# csr register map
Vendor: litex
Litex SoC 2024-01-17 20:17:24
Registers are 32-bit, read-write, reset 0x0 unless marked. A register's access mark holds for its fields unless they carry their own. Offsets are from the block's base; lines under a group give offsets from that group; [hi:lo] are bit positions; {n}, {i} and the like mark numbered series; 'fields as' and 'values as' point back to an identical list; <NAME> marks a mode.

## Memory map
0x82000000 LEDS size 0x4
0x82000800 PANTALLA size 0x1C
0x82001000 CTRL size 0xC
0x82001800 ETHMAC size 0x44
0x82002000 ETHPHY size 0x10
0x82002800 IDENTIFIER_MEM size 0x4
0x82003000 SDRAM size 0x1C
0x82003800 TIMER0 size 0x20
0x82004000 UART size 0x20

## Interrupts
0 uart (UART)
1 timer0 (TIMER0)
2 ethmac (ETHMAC)

## Further device data
memoryRegions:
  ROM baseAddress=0x00000000 size=0x00009800
  SRAM baseAddress=0x01000000 size=0x00002000
  MAIN_RAM baseAddress=0x40000000 size=0x00800000
  ETHMAC baseAddress=0x80000000 size=0x00002000
  CSR baseAddress=0x82000000 size=0x00010000
constants:
  CONFIG_CLOCK_FREQUENCY value=60000000
  CONFIG_CPU_HAS_INTERRUPT value=None
  CONFIG_CPU_RESET_ADDR value=0
  CONFIG_CPU_TYPE_LM32 value=None
  CONFIG_CPU_VARIANT_STANDARD value=None
  CONFIG_CPU_HUMAN_NAME value=LM32
  CONFIG_CPU_NOP value=nop
  CONFIG_L2_SIZE value=8192
  CONFIG_CSR_DATA_WIDTH value=32
  CONFIG_CSR_ALIGNMENT value=32
  CONFIG_BUS_STANDARD value=WISHBONE
  CONFIG_BUS_DATA_WIDTH value=32
  CONFIG_BUS_ADDRESS_WIDTH value=32
  CONFIG_BUS_BURSTING value=0
  ETHMAC_RX_SLOTS value=2
  ETHMAC_TX_SLOTS value=2
  ETHMAC_SLOT_SIZE value=2048
  CONFIG_CPU_INTERRUPTS value=3
  ETHMAC_INTERRUPT value=2
  TIMER0_INTERRUPT value=1
  UART_INTERRUPT value=0

## LEDS
Base 0x82000000
0x00 OUT — GPIO Output(s) Control.
  [0] out

## PANTALLA
Base 0x82000800
0x00 ENABLE
  [0] enable
0x04 WR
  [0] wr
0x08 DATALINE1 — Bits 32-53 of `PANTALLA_DATALINE`.
  [31:0] dataline
0x0C DATALINE0 — Bits 0-31 of `PANTALLA_DATALINE`.
  [31:0] dataline
0x10 ADDRWRITE
  [11:0] addrwrite
0x14 RAMTIME
  [29:0] ramtime
0x18 REQUIREDATA
  [0] requiredata

## CTRL
Base 0x82001000
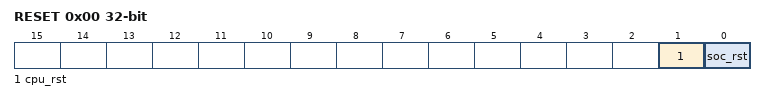
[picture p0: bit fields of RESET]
0x00 RESET
  [1] cpu_rst — Write `1` to this register to reset the CPU(s) of the SoC (Hold Reset)
  [0] soc_rst — Write `1` to this register to reset the full SoC (Pulse Reset)
0x04 SCRATCH reset 0x12345678 — Use this register as a scratch space to verify that software read/write accesses to the Wishbone/CSR bus are working correctly. The initial reset value of 0x1234578 can be used to verify endianness.
0x08 BUS_ERRORS — Total number of Wishbone bus errors (timeouts) since start.

## ETHMAC
Base 0x82001800
0x00 SRAM_WRITER_SLOT
  [0] sram_writer_slot
0x04 SRAM_WRITER_LENGTH
  [10:0] sram_writer_length
0x08 SRAM_WRITER_ERRORS
0x0C SRAM_WRITER_EV_STATUS — This register contains the current raw level of the available event trigger. Writes to this register have no effect.
  [0] available — Level of the ``available`` event
0x10 SRAM_WRITER_EV_PENDING — When a available event occurs, the corresponding bit will be set in this register. To clear the Event, set the corresponding bit in this register.
  [0] available — `1` if a `available` event occurred. This Event is **level triggered** when the signal is **high**.
0x14 SRAM_WRITER_EV_ENABLE — This register enables the corresponding available events. Write a ``0`` to this register to disable individual events.
  [0] available — Write a ``1`` to enable the ``available`` Event
0x18 SRAM_READER_START
  [0] sram_reader_start
0x1C SRAM_READER_READY
  [0] sram_reader_ready
0x20 SRAM_READER_LEVEL
  [1:0] sram_reader_level
0x24 SRAM_READER_SLOT
  [0] sram_reader_slot
0x28 SRAM_READER_LENGTH
  [10:0] sram_reader_length
0x2C SRAM_READER_EV_STATUS — This register contains the current raw level of the event0 event trigger. Writes to this register have no effect.
  [0] event0 — Level of the ``event0`` event
0x30 SRAM_READER_EV_PENDING — When a event0 event occurs, the corresponding bit will be set in this register. To clear the Event, set the corresponding bit in this register.
  [0] event0 — `1` if a this particular event occurred. This Event is triggered on a **rising** edge.
0x34 SRAM_READER_EV_ENABLE — This register enables the corresponding event0 events. Write a ``0`` to this register to disable individual events.
  [0] event0 — Write a ``1`` to enable the ``event0`` Event
0x38 PREAMBLE_CRC reset 0x1
  [0] preamble_crc
0x3C RX_DATAPATH_PREAMBLE_ERRORS
0x40 RX_DATAPATH_CRC_ERRORS

## ETHPHY
Base 0x82002000
0x00 CRG_RESET
  [0] crg_reset
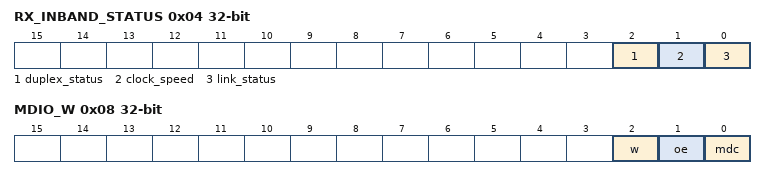
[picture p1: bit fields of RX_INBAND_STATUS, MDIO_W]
0x04 RX_INBAND_STATUS
  [2] duplex_status, [1] clock_speed, [0] link_status
0x08 MDIO_W
  [2] w, [1] oe, [0] mdc
0x0C MDIO_R
  [0] r

## IDENTIFIER_MEM
Base 0x82002800
0x00 IDENTIFIER_MEM — 8 x 45-bit memory
  [7:0] identifier_mem

## SDRAM
Base 0x82003000
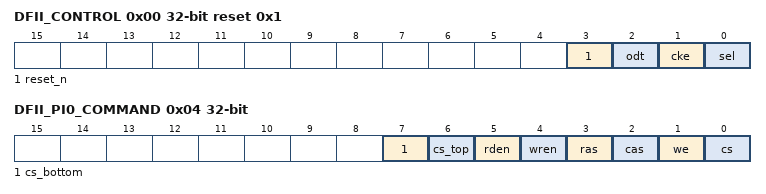
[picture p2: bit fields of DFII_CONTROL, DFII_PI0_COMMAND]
0x00 DFII_CONTROL reset 0x1 — Control DFI signals common to all phases
  [3] reset_n — DFI clock reset bus
  [2] odt — DFI on-die termination bus
  [1] cke — DFI clock enable bus
  [0] sel
0x04 DFII_PI0_COMMAND — Control DFI signals on a single phase
  [7] cs_bottom — DFI chip select bus for bottom half only
  [6] cs_top — DFI chip select bus for top half only
  [5] rden — DFI read data enable bus
  [4] wren — DFI write data enable bus
  [3] ras — DFI row address strobe bus
  [2] cas — DFI column address strobe bus
  [1] we — DFI write enable bus
  [0] cs — DFI chip select bus
0x08 DFII_PI0_COMMAND_ISSUE
  [0] dfii_pi0_command_issue
0x0C DFII_PI0_ADDRESS — DFI address bus
  [10:0] dfii_pi0_address
0x10 DFII_PI0_BADDRESS — DFI bank address bus
  [1:0] dfii_pi0_baddress
0x14 DFII_PI0_WRDATA — DFI write data bus
0x18 DFII_PI0_RDDATA — DFI read data bus

## TIMER0
Base 0x82003800
0x00 LOAD — Load value when Timer is (re-)enabled. In One-Shot mode, the value written to this register specifies the Timer's duration in clock cycles.
0x04 RELOAD — Reload value when Timer reaches ``0``. In Periodic mode, the value written to this register specify the Timer's period in clock cycles.
0x08 EN — Enable flag of the Timer. Set this flag to ``1`` to enable/start the Timer. Set to ``0`` to disable the Timer.
  [0] en
0x0C UPDATE_VALUE — Update trigger for the current countdown value. A write to this register latches the current countdown value to ``value`` register.
  [0] update_value
0x10 VALUE — Latched countdown value. This value is updated by writing to ``update_value``.
0x14 EV_STATUS — This register contains the current raw level of the zero event trigger. Writes to this register have no effect.
  [0] zero — Level of the ``zero`` event
0x18 EV_PENDING — When a zero event occurs, the corresponding bit will be set in this register. To clear the Event, set the corresponding bit in this register.
  [0] zero — `1` if a `zero` event occurred. This Event is triggered on a **falling** edge.
0x1C EV_ENABLE — This register enables the corresponding zero events. Write a ``0`` to this register to disable individual events.
  [0] zero — Write a ``1`` to enable the ``zero`` Event

## UART
Base 0x82004000
0x00 RXTX
  [7:0] rxtx
0x04 TXFULL — TX FIFO Full.
  [0] txfull
0x08 RXEMPTY — RX FIFO Empty.
  [0] rxempty
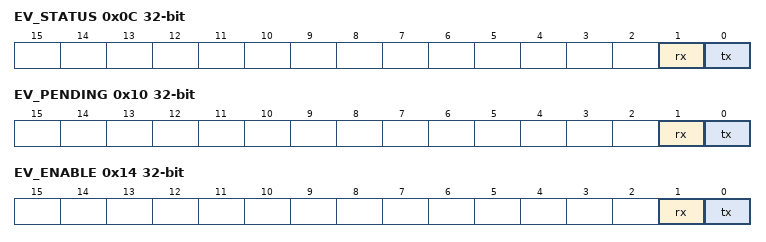
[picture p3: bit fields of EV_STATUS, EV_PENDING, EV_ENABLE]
0x0C EV_STATUS — This register contains the current raw level of the rx event trigger. Writes to this register have no effect.
  [1] rx — Level of the ``rx`` event
  [0] tx — Level of the ``tx`` event
0x10 EV_PENDING — When a rx event occurs, the corresponding bit will be set in this register. To clear the Event, set the corresponding bit in this register.
  [1] rx — `1` if a `rx` event occurred. This Event is triggered on a **falling** edge.
  [0] tx — `1` if a `tx` event occurred. This Event is triggered on a **falling** edge.
0x14 EV_ENABLE — This register enables the corresponding rx events. Write a ``0`` to this register to disable individual events.
  [1] rx — Write a ``1`` to enable the ``rx`` Event
  [0] tx — Write a ``1`` to enable the ``tx`` Event
0x18 TXEMPTY — TX FIFO Empty.
  [0] txempty
0x1C RXFULL — RX FIFO Full.
  [0] rxfull
